AUTOSAR XML (schema 4-3-0)
package /Impl_SWC_DID_ARPkg
  swc implementation Impl_SWC_DID_type: programming-language=C, sw-version=1.0.0, vendor-id=0, behavior=SWC_DID_type_IB
    code-descriptors:
      code SRC: artifact-descriptors=autosar-engineering-object={short-label=EngObject, category=SWSRC}
    resource consumption ResourceConsumption
      memory section Mem_SWC_DID_CODE: size=0, sw-addrmethod=CODE, symbol=CODE
package /Interface_DID_ARPkg
  client server interface IF_DIDReadCDD
    operation CSOP_DIDGet_AutoLock
      4 x arg, all with server-argument-impl-policy=USE-ARGUMENT-TYPE:
        u8_AutoLock: type=uint8, direction=OUT
        u8_DIDSta_AutoLock: type=uint8, direction=OUT
        u16_DIDNum_AutoLock: type=uint16, direction=IN
        u16_DIDLen_AutoLock: type=uint16, direction=IN
  client server interface IF_DIDWriteCDD
    operation CSOP_DIDSet_AutoLock
      arg u16_DIDNum_AutoLock: type=uint16, direction=IN, server-argument-impl-policy=USE-ARGUMENT-TYPE
      arg u16_DIDLen_AutoLock: type=uint16, direction=IN, server-argument-impl-policy=USE-ARGUMENT-TYPE
      arg u8_AutoLock: type=uint8, direction=IN, server-argument-impl-policy=USE-ARGUMENT-TYPE
package /SWC_DID_ARPkg
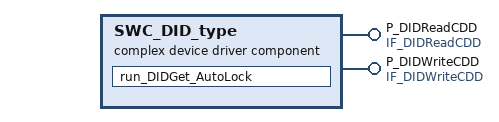
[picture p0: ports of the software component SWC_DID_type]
  complex device driver sw component type SWC_DID_type
    provide port P_DIDReadCDD: provided-interface=IF_DIDReadCDD
    provide port P_DIDWriteCDD: provided-interface=IF_DIDWriteCDD
    behavior SWC_DID_type_IB: handle-termination-and-restart=NO-SUPPORT
      operation invoked event oie_P_DIDReadCDD_CSOP_DIDGet_AutoLock: start-on-event=run_DIDGet_AutoLock, operation=P_DIDReadCDD.CSOP_DIDGet_AutoLock
      port-api-options:
        enable-take-address=false, indirect-api=false, port=P_DIDWriteCDD
        enable-take-address=false, indirect-api=false, port=P_DIDReadCDD
      runnable run_DIDGet_AutoLock
package /TypeDef_DID_ARPkg
  impl type u8Array8_DKCKey_type: category=ARRAY
    element u8_Element: category=VALUE, array-size=8, array-size-semantics=FIXED-SIZE, base-type=uint8
